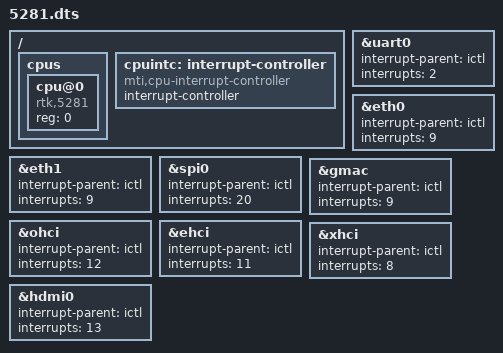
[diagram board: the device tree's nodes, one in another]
/*
 * Realtek Semiconductor Corp.
 *
 * Device Tree Structure
 *
 * Tony Wu (tonywu@realtek.com)
 */

/dts-v1/;

#include <dt-bindings/interrupt-controller/mips-gic.h>
#include "sheipa.dtsi"

/ {
	#address-cells = <1>;
	#size-cells = <1>;

	cpus {
		#address-cells = <1>;
		#size-cells = <0>;

		cpu@0 {
			compatible = "rtk,5281";
			device_type = "cpu";
			reg = <0>;
		};
	};

	cpuintc: interrupt-controller {
		#address-cells = <0>;
		#interrupt-cells = <1>;
		interrupt-controller;
		compatible = "mti,cpu-interrupt-controller";
	};

};

&uart0 {
	interrupt-parent = <&ictl>;
	interrupts = <2>;
};

&eth0 {
	interrupt-parent = <&ictl>;
	interrupts = <9>;
};

&eth1 {
	interrupt-parent = <&ictl>;
	interrupts = <9>;
};

&spi0 {
	interrupt-parent = <&ictl>;
	interrupts = <20>;
};

&gmac {
	interrupt-parent = <&ictl>;
	interrupts = <9>;
};

&ohci {
	interrupt-parent = <&ictl>;
	interrupts = <12>;
};

&ehci {
	interrupt-parent = <&ictl>;
	interrupts = <11>;
};

&xhci {
	interrupt-parent = <&ictl>;
	interrupts = <8>;
};

&hdmi0 {
	interrupt-parent = <&ictl>;
	interrupts = <13>;
};
